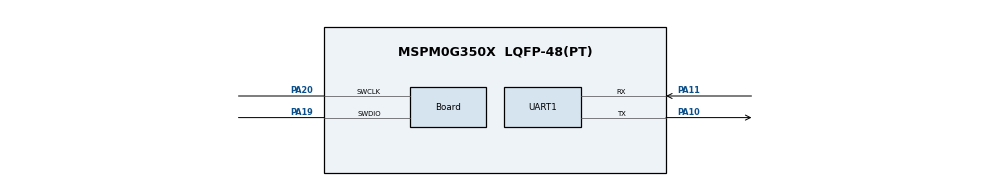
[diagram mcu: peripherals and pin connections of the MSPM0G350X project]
/**
 * @cliArgs --device "MSPM0G350X" --part "Default" --package "LQFP-48(PT)" --product "mspm0_sdk@2.04.00.06"
 * @versions {"tool":"1.22.0+3893"}
 */

/**
 * Import the modules used in this configuration.
 */
const GPIO    = scripting.addModule("/ti/driverlib/GPIO", {}, false);
const GPIO1   = GPIO.addInstance();
const SYSCTL  = scripting.addModule("/ti/driverlib/SYSCTL");
const SYSTICK = scripting.addModule("/ti/driverlib/SYSTICK");
const UART    = scripting.addModule("/ti/driverlib/UART", {}, false);
const UART1   = UART.addInstance();

/**
 * Write custom configuration values to the imported modules.
 */
const gate7  = system.clockTree["MFCLKGATE"];
gate7.enable = true;

GPIO1.$name                          = "BSL";
GPIO1.associatedPins[0].$name        = "PIN_18";
GPIO1.associatedPins[0].assignedPin  = "18";
GPIO1.associatedPins[0].assignedPort = "PORTA";

const Board                       = scripting.addModule("/ti/driverlib/Board", {}, false);
Board.peripheral.$assign          = "DEBUGSS";
Board.peripheral.swclkPin.$assign = "PA20";
Board.peripheral.swdioPin.$assign = "PA19";

SYSCTL.forceDefaultClkConfig = true;
SYSCTL.clockTreeEn           = true;

SYSTICK.periodEnable      = true;
SYSTICK.period            = 32000;
SYSTICK.interruptEnable   = true;
SYSTICK.systickEnable     = true;
SYSTICK.interruptPriority = "0";

UART1.$name                    = "UART_0";
UART1.uartClkSrc               = "MFCLK";
UART1.enabledInterrupts        = ["RX"];
UART1.peripheral.$assign       = "UART0";
UART1.peripheral.rxPin.$assign = "PA11";
UART1.peripheral.txPin.$assign = "PA10";
UART1.txPinConfig.$name        = "ti_driverlib_gpio_GPIOPinGeneric0";
UART1.rxPinConfig.$name        = "ti_driverlib_gpio_GPIOPinGeneric1";

const ProjectConfig              = scripting.addModule("/ti/project_config/ProjectConfig", {}, false);
ProjectConfig.migrationCondition = true;

/**
 * Pinmux solution for unlocked pins/peripherals. This ensures that minor changes to the automatic solver in a future
 * version of the tool will not impact the pinmux you originally saw.  These lines can be completely deleted in order to
 * re-solve from scratch.
 */
GPIO1.associatedPins[0].pin.$suggestSolution = "PA18";
